# QN908XC register map
Vendor: nxp.com; File version: 1.0
CPU: CM4 r0p1, little endian, no MPU, no FPU, 0x3 interrupt priority bits, 0x0 interrupts
Registers are 32-bit, read-write, reset 0x0 unless marked. A register's access mark holds for its fields unless they carry their own. Offsets are from the block's base; [hi:lo] are bit positions; {n}, {i} and the like mark numbered series; 'fields as' and 'values as' point back to an identical list.

## SPI0 — spi
Base 0x40087000
Same registers: SPI1 0x4008F000
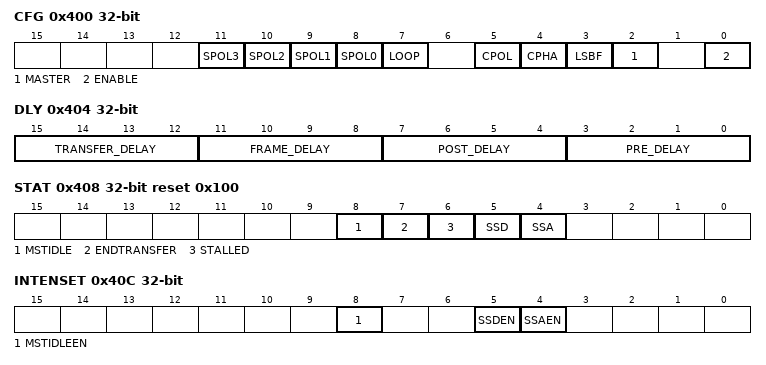
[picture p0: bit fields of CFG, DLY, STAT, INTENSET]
0x400 CFG — SPI Configuration register
  [n+8] SPOL{n} (n=0..3) — SSEL{n} Polarity select.
    0=LOW (Low. The SSEL{n} pin is active low.); 1=HIGH (High. The SSEL{n} pin is active high.)
  [7] LOOP — Loopback mode enable. Loopback mode applies only to Master mode, and connects transmit and receive data connected together to allow simple software testing.
    0=DISABLED; 1=ENABLED
  [5] CPOL — Clock Polarity select.
    0=LOW (Low. The rest state of the clock (between transfers) is low.); 1=HIGH (High. The rest state of the clock (between transfers) is high.)
  [4] CPHA — Clock Phase select.
    0=CHANGE (Change. The SPI captures serial data on the first clock transition of the transfer (when the clock changes away from the rest state). Data is changed on the following edge.); 1=CAPTURE (Capture. The SPI changes serial data on the first clock transition of the transfer (when the clock changes away from the rest state). Data is captured on the following edge.)
  [3] LSBF — LSB First mode enable.
    0=STANDARD (Standard. Data is transmitted and received in standard MSB first order.); 1=REVERSE (Reverse. Data is transmitted and received in reverse order (LSB first).)
  [2] MASTER — Master mode select.
    0=SLAVE_MODE (Slave mode. The SPI will operate in slave mode. SCK, MOSI, and the SSEL signals are inputs, MISO is an output.); 1=MASTER_MODE (Master mode. The SPI will operate in master mode. SCK, MOSI, and the SSEL signals are outputs, MISO is an input.)
  [0] ENABLE — SPI enable.
    0=DISABLED (Disabled. The SPI is disabled and the internal state machine and counters are reset.); 1=ENABLED (Enabled. The SPI is enabled for operation.)
0x404 DLY — SPI Delay register
  [15:12] TRANSFER_DELAY — Controls the minimum amount of time that the SSEL is deasserted between transfers. 0x0 = The minimum time that SSEL is deasserted is 1 SPI clock time. (Zero added time.) 0x1 = The minimum time that SSEL is deasserted is 2 SPI clock times. 0x2 = The minimum time that SSEL is deasserted is 3 SPI clock times. 0xF = The minimum time that SSEL is deasserted is 16 SPI clock times.
  [11:8] FRAME_DELAY — If the EOF flag is set, controls the minimum amount of time between the current frame and the next frame (or SSEL deassertion if EOT). 0x0 = No additional time is inserted. 0x1 = 1 SPI clock time is inserted. 0x2 = 2 SPI clock times are inserted. 0xF = 15 SPI clock times are inserted.
  [7:4] POST_DELAY — Controls the amount of time between the end of a data transfer and SSEL deassertion. 0x0 = No additional time is inserted. 0x1 = 1 SPI clock time is inserted. 0x2 = 2 SPI clock times are inserted. 0xF = 15 SPI clock times are inserted.
  [3:0] PRE_DELAY — Controls the amount of time between SSEL assertion and the beginning of a data transfer. There is always one SPI clock time between SSEL assertion and the first clock edge. This is not considered part of the pre-delay. 0x0 = No additional time is inserted. 0x1 = 1 SPI clock time is inserted. 0x2 = 2 SPI clock times are inserted. 0xF = 15 SPI clock times are inserted.
0x408 STAT reset 0x100 (reset mask 0x1C0) — SPI Status. Some status flags can be cleared by writing a 1 to that bit position.
  [8] MSTIDLE ro — Master idle status flag. This bit is 1 whenever the SPI master function is fully idle. This means that the transmit holding register is empty and the transmitter is not in the process of sending data.
  [7] ENDTRANSFER — End Transfer control bit. Software can set this bit to force an end to the current transfer when the transmitter finishes any activity already in progress, as if the EOT flag had been set prior to the last transmission. This capability is included to support cases where it is not known when transmit data is written that it will be the end of a transfer. The bit is cleared when the transmitter becomes idle as the transfer comes to an end. Forcing an end of transfer in this manner causes any specified FRAME_DELAY and TRANSFER_DELAY to be inserted.
  [6] STALLED ro — Stalled status flag. This indicates whether the SPI is currently in a stall condition.
  [5] SSD wo — Slave Select Deassert. This flag is set whenever any asserted slave selects transition to deasserted, in both master and slave modes. This allows determining when the SPI transmit/receive functions become idle. This flag is cleared by software.
  [4] SSA wo — Slave Select Assert. This flag is set whenever any slave select transitions from deasserted to asserted, in both master and slave modes. This allows determining when the SPI transmit/receive functions become busy, and allows waking up the device from reduced power modes when a slave mode access begins. This flag is cleared by software.
0x40C INTENSET — SPI Interrupt Enable read and Set. A complete value may be read from this register. Writing a 1 to any implemented bit position causes that bit to be set.
  [8] MSTIDLEEN — Master idle interrupt enable.
    0=DISABLED (No interrupt will be generated when the SPI master function is idle.); 1=ENABLED (An interrupt will be generated when the SPI master function is fully idle.)
  [5] SSDEN — Slave select deassert interrupt enable. Determines whether an interrupt occurs when the Slave Select is deasserted.
    0=DISABLED (Disabled. No interrupt will be generated when all asserted Slave Selects transition to deasserted.); 1=ENABLED (Enabled. An interrupt will be generated when all asserted Slave Selects transition to deasserted.)
  [4] SSAEN — Slave select assert interrupt enable. Determines whether an interrupt occurs when the Slave Select is asserted.
    0=DISABLED (Disabled. No interrupt will be generated when any Slave Select transitions from deasserted to asserted.); 1=ENABLED (Enabled. An interrupt will be generated when any Slave Select transitions from deasserted to asserted.)
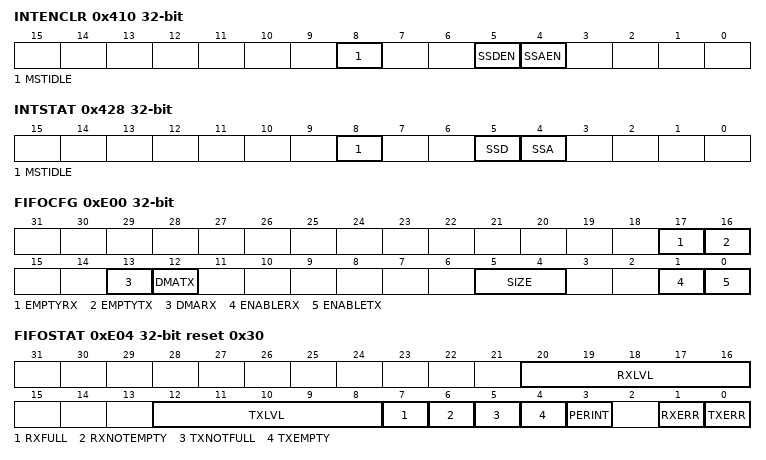
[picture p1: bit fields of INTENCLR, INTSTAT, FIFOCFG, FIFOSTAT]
0x410 INTENCLR wo reset not defined — SPI Interrupt Enable Clear. Writing a 1 to any implemented bit position causes the corresponding bit in INTENSET to be cleared.
  [8] MSTIDLE — Writing 1 clears the corresponding bit in the INTENSET register.
  [5] SSDEN — Writing 1 clears the corresponding bit in the INTENSET register.
  [4] SSAEN — Writing 1 clears the corresponding bit in the INTENSET register.
0x424 DIV — SPI clock Divider
  [15:0] DIVVAL — Rate divider value. Specifies how the Flexcomm clock (FCLK) is divided to produce the SPI clock rate in master mode. DIVVAL is -1 encoded such that the value 0 results in FCLK/1, the value 1 results in FCLK/2, up to the maximum possible divide value of 0xFFFF, which results in FCLK/65536.
0x428 INTSTAT ro — SPI Interrupt Status
  [8] MSTIDLE — Master Idle status flag.
  [5] SSD — Slave Select Deassert.
  [4] SSA — Slave Select Assert.
0xE00 FIFOCFG (reset mask 0x4F033) — FIFO configuration and enable register.
  [17] EMPTYRX wo — Empty command for the receive FIFO. When a 1 is written to this bit, the RX FIFO is emptied.
  [16] EMPTYTX wo — Empty command for the transmit FIFO. When a 1 is written to this bit, the TX FIFO is emptied.
  [13] DMARX — DMA configuration for receive.
    0=NOT_TRIGGERED (DMA is not used for the receive function.); 1=TRIGGERED (Trigger DMA for the receive function if the FIFO is not empty. Generally, data interrupts would be disabled if DMA is enabled.)
  [12] DMATX — DMA configuration for transmit.
    0=NOT_TRIGGERED (DMA is not used for the transmit function.); 1=TRIGGERED (Trigger DMA for the transmit function if the FIFO is not full. Generally, data interrupts would be disabled if DMA is enabled.)
  [5:4] SIZE ro — FIFO size configuration. This is a read-only field. 0x1 = FIFO is configured as 8 entries of 16 bits. 0x0, 0x2, 0x3 = not applicable to SPI.
  [1] ENABLERX — Enable the receive FIFO.
    0=DISABLED (The transmit FIFO is not enabled.); 1=ENABLED (The transmit FIFO is enabled.)
  [0] ENABLETX — Enable the transmit FIFO.
    values as ENABLERX
0xE04 FIFOSTAT reset 0x30 — FIFO status register.
  [20:16] RXLVL ro — Receive FIFO current level. A 0 means the RX FIFO is currently empty, and the RXFULL and RXNOTEMPTY flags will be 0. Other values tell how much data is actually in the RX FIFO at the point where the read occurs. If the RX FIFO is full, the RXFULL and RXNOTEMPTY flags will be 1.
  [12:8] TXLVL ro — Transmit FIFO current level. A 0 means the TX FIFO is currently empty, and the TXEMPTY and TXNOTFULL flags will be 1. Other values tell how much data is actually in the TX FIFO at the point where the read occurs. If the TX FIFO is full, the TXEMPTY and TXNOTFULL flags will be 0.
  [7] RXFULL ro — Receive FIFO full. When 1, the receive FIFO is full. Data needs to be read out to prevent the peripheral from causing an overflow.
  [6] RXNOTEMPTY ro — Receive FIFO not empty. When 1, the receive FIFO is not empty, so data can be read. When 0, the receive FIFO is empty.
  [5] TXNOTFULL ro — Transmit FIFO not full. When 1, the transmit FIFO is not full, so more data can be written. When 0, the transmit FIFO is full and another write would cause it to overflow.
  [4] TXEMPTY ro — Transmit FIFO empty. When 1, the transmit FIFO is empty. The peripheral may still be processing the last piece of data.
  [3] PERINT ro — Peripheral interrupt. When 1, this indicates that the peripheral function has asserted an interrupt. The details can be found by reading the peripheral' STAT register.
  [1] RXERR — RX FIFO error. Will be set if a receive FIFO overflow occurs, caused by software or DMA not emptying the FIFO fast enough. Cleared by writing a 1 to this bit.
  [0] TXERR — TX FIFO error. Will be set if a transmit FIFO error occurs. This could be an overflow caused by pushing data into a full FIFO, or by an underflow if the FIFO is empty when data is needed. Cleared by writing a 1 to this bit.
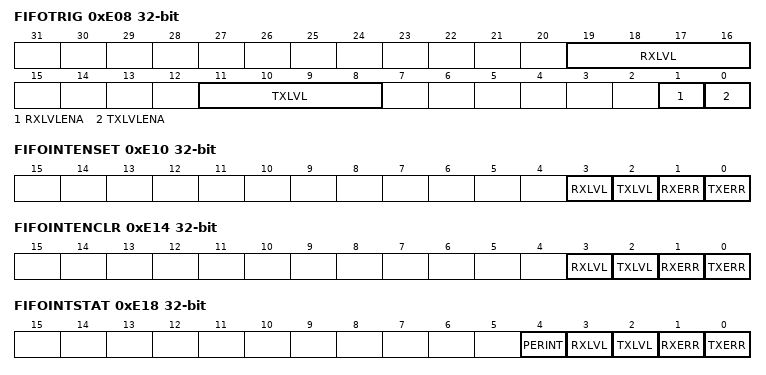
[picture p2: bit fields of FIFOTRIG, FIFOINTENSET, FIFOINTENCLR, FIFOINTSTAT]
0xE08 FIFOTRIG — FIFO trigger settings for interrupt and DMA request.
  [19:16] RXLVL — Receive FIFO level trigger point. The RX FIFO level is checked when a new piece of data is received. This field is used only when RXLVLENA = 1. If enabled to do so, the FIFO level can wake up the device just enough to perform DMA, then return to the reduced power mode See -Hardware Wake-up control register-. 0 = trigger when the RX FIFO has received one entry (is no longer empty). 1 = trigger when the RX FIFO has received two entries. 7 = trigger when the RX FIFO has received 8 entries (has become full).
  [11:8] TXLVL — Transmit FIFO level trigger point. This field is used only when TXLVLENA = 1. If enabled to do so, the FIFO level can wake up the device just enough to perform DMA, then return to the reduced power mode See -Hardware Wake-up control register-. 0 = trigger when the TX FIFO becomes empty. 1 = trigger when the TX FIFO level decreases to one entry. 7 = 1 = trigger when the TX FIFO level decreases to 7 entries (is no longer full).
  [1] RXLVLENA — Receive FIFO level trigger enable. This trigger will become an interrupt if enabled in FIFOINTENSET, or a DMA trigger if DMARX in FIFOCFG is set.
    0=DISABLED (Receive FIFO level does not generate a FIFO level trigger.); 1=ENABLED (An trigger will be generated if the receive FIFO level reaches the value specified by the RXLVL field in this register.)
  [0] TXLVLENA — Transmit FIFO level trigger enable. This trigger will become an interrupt if enabled in FIFOINTENSET, or a DMA trigger if DMATX in FIFOCFG is set.
    0=DISABLED (Transmit FIFO level does not generate a FIFO level trigger.); 1=ENABLED (An trigger will be generated if the transmit FIFO level reaches the value specified by the TXLVL field in this register.)
0xE10 FIFOINTENSET — FIFO interrupt enable set (enable) and read register.
  [3] RXLVL — Determines whether an interrupt occurs when a the receive FIFO reaches the level specified by the TXLVL field in the FIFOTRIG register.
    0=DISABLED (No interrupt will be generated based on the RX FIFO level.); 1=ENABLED (If RXLVLENA in the FIFOTRIG register = 1, an interrupt will be generated when the when the RX FIFO level increases to the level specified by RXLVL in the FIFOTRIG register.)
  [2] TXLVL — Determines whether an interrupt occurs when a the transmit FIFO reaches the level specified by the TXLVL field in the FIFOTRIG register.
    0=DISABLED (No interrupt will be generated based on the TX FIFO level.); 1=ENABLED (If TXLVLENA in the FIFOTRIG register = 1, an interrupt will be generated when the TX FIFO level decreases to the level specified by TXLVL in the FIFOTRIG register.)
  [1] RXERR — Determines whether an interrupt occurs when a receive error occurs, based on the RXERR flag in the FIFOSTAT register.
    0=DISABLED (No interrupt will be generated for a receive error.); 1=ENABLED (An interrupt will be generated when a receive error occurs.)
  [0] TXERR — Determines whether an interrupt occurs when a transmit error occurs, based on the TXERR flag in the FIFOSTAT register.
    0=DISABLED (No interrupt will be generated for a transmit error.); 1=ENABLED (An interrupt will be generated when a transmit error occurs.)
0xE14 FIFOINTENCLR — FIFO interrupt enable clear (disable) and read register.
  [3] RXLVL — Writing one clears the corresponding bits in the FIFOINTENSET register.
  [2] TXLVL — Writing one clears the corresponding bits in the FIFOINTENSET register.
  [1] RXERR — Writing one clears the corresponding bits in the FIFOINTENSET register.
  [0] TXERR — Writing one clears the corresponding bits in the FIFOINTENSET register.
0xE18 FIFOINTSTAT ro — FIFO interrupt status register.
  [4] PERINT — Peripheral interrupt.
  [3] RXLVL — Receive FIFO level interrupt.
  [2] TXLVL — Transmit FIFO level interrupt.
  [1] RXERR — RX FIFO error.
  [0] TXERR — TX FIFO error.
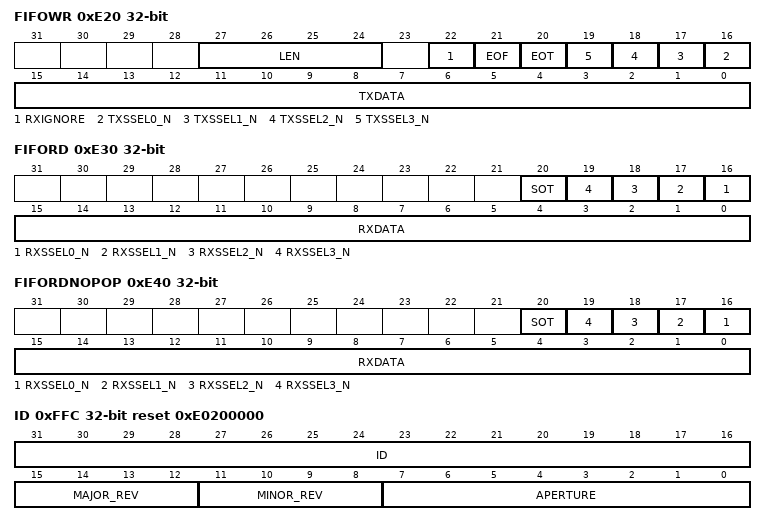
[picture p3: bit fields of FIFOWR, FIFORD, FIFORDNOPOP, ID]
0xE20 FIFOWR reset not defined — FIFO write data.
  [27:24] LEN wo — Data Length. Specifies the data length from 1 to 16 bits. Note that transfer lengths greater than 16 bits are supported by implementing multiple sequential transmits. 0x0 = Data transfer is 1 bit in length. Note: when LEN = 0, the underrun status is not meaningful. 0x1 = Data transfer is 2 bits in length. 0x2 = Data transfer is 3 bits in length. 0xF = Data transfer is 16 bits in length.
  [22] RXIGNORE wo — Receive Ignore. This allows data to be transmitted using the SPI without the need to read unneeded data from the receiver.Setting this bit simplifies the transmit process and can be used with the DMA.
    0=READ (Read received data. Received data must be read in order to allow transmission to progress. In slave mode, an overrun error will occur if received data is not read before new data is received.); 1=IGNORE (Ignore received data. Received data is ignored, allowing transmission without reading unneeded received data. No receiver flags are generated.)
  [21] EOF wo — End of Frame. Between frames, a delay may be inserted, as defined by the FRAME_DELAY value in the DLY register. The end of a frame may not be particularly meaningful if the FRAME_DELAY value = 0. This control can be used as part of the support for frame lengths greater than 16 bits.
    0=NOT_EOF (Data not EOF. This piece of data transmitted is not treated as the end of a frame.); 1=EOF (Data EOF. This piece of data is treated as the end of a frame, causing the FRAME_DELAY time to be inserted before subsequent data is transmitted.)
  [20] EOT wo — End of Transfer. The asserted SSEL will be deasserted at the end of a transfer, and remain so for at least the time specified by the Transfer_delay value in the DLY register.
    0=NOT_DEASSERTED (SSEL not deasserted. This piece of data is not treated as the end of a transfer. SSEL will not be deasserted at the end of this data.); 1=DEASSERTED (SSEL deasserted. This piece of data is treated as the end of a transfer. SSEL will be deasserted at the end of this piece of data.)
  [n+16] TXSSEL{n}_N wo (n=0..3) — Transmit Slave Select. This field asserts SSEL{n} in master mode. The output on the pin is active LOW by default. Remark: The active state of the SSEL{n} pin is configured by bits in the CFG register.
    0=ASSERTED (SSEL{n} asserted.); 1=NOT_ASSERTED (SSEL{n} not asserted.)
  [15:0] TXDATA wo — Transmit data to the FIFO.
0xE30 FIFORD ro — FIFO read data.
  [20] SOT — Start of Transfer flag. This flag will be 1 if this is the first data after the SSELs went from deasserted to asserted (i.e., any previous transfer has ended). This information can be used to identify the first piece of data in cases where the transfer length is greater than 16 bit.
  [n+16] RXSSEL{n}_N (n=0..3) — Slave Select for receive. This field allows the state of the SSEL{n} pin to be saved along with received data. The value will reflect the SSEL{n} pin for both master and slave operation. A zero indicates that a slave select is active. The actual polarity of each slave select pin is configured by the related SPOL bit in CFG.
  [15:0] RXDATA — Received data from the FIFO.
0xE40 FIFORDNOPOP ro — FIFO data read with no FIFO pop.
  fields as FIFORD
0xFFC ID ro reset 0xE0200000 — SPI module Identification. This value appears in the shared Flexcomm peripheral ID register when SPI is selected.
  [31:16] ID — Unique module identifier for this IP block.
  [15:12] MAJOR_REV — Major revision of module implementation, starting at 0. There may not be software compatibility between major revisions.
  [11:8] MINOR_REV — Minor revision of module implementation, starting at 0. Minor revision of module implementation, starting at 0. Software compatibility is expected between minor revisions.
  [7:0] APERTURE — Aperture: encoded as (aperture size/4K) -1, so 0x00 means a 4K aperture.
